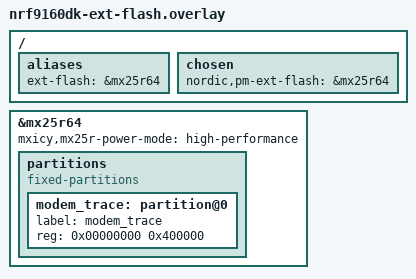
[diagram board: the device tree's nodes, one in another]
/*
 * Copyright (c) 2024 Nordic Semiconductor ASA
 *
 * SPDX-License-Identifier: LicenseRef-Nordic-5-Clause
 */

&mx25r64 {
	status = "okay";
	mxicy,mx25r-power-mode = "high-performance";

	partitions {
		compatible = "fixed-partitions";
		#address-cells = <1>;
		#size-cells = <1>;

		modem_trace: partition@0 {
			label = "modem_trace";
			reg = <0x00000000 0x400000>;
		};
	};
};

/ {
	aliases {
		ext-flash = &mx25r64;
	};

	/* Configure partition manager to use mx25r64 as the external flash */
	chosen {
		nordic,pm-ext-flash = &mx25r64;
	};
};
